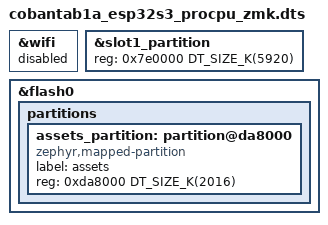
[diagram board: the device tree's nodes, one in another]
/*
 * Copyright (c) 2026 The ZMK Contributors
 *
 * SPDX-License-Identifier: MIT
 */

#include "cobantab1a_esp32s3_procpu.dts"

/*
 * ZMK variant of the Coban Tab 1a.
 *
 * - BLE HID unplugged; the shield overlay (zmk-config) turns on DWC2 OTG for a
 *   wired HID + Studio-RPC-CDC composite, handing GPIO19/20 from Serial/JTAG to
 *   OTG at run time (no eFuse), so flashing stays on the ROM loader while the
 *   console and shell move to UART0 (GPIO43/44, P1 header).
 * - Settings live in the labelled 192 KiB `storage` partition; Wi-Fi is off.
 * - PSRAM (8 MB octal) is enabled: the display stream and the LVGL heap live
 *   there.
 * - `assets` (2016 KiB @ 0xda8000, manifest + blobs from
 *   app/scripts/display-assets/pack_assets.py) is carved out of the unused
 *   MCUboot OTA slot. The arithmetic is load-bearing: slot1 must end exactly at
 *   0xda8000 (0x7e0000 + 5920K) and assets at 0xfa0000, or uploads would overlap
 *   slot1's tail or slot0_lpcore.
 */

&wifi {
    status = "disabled";
};

&slot1_partition {
    reg = <0x7e0000 DT_SIZE_K(5920)>; /* ends exactly at assets 0xda8000 */
};

&flash0 {
    partitions {
        assets_partition: partition@da8000 {
            compatible = "zephyr,mapped-partition";
            label = "assets";
            reg = <0xda8000 DT_SIZE_K(2016)>; /* ends at slot0_lpcore */
        };
    };
};
